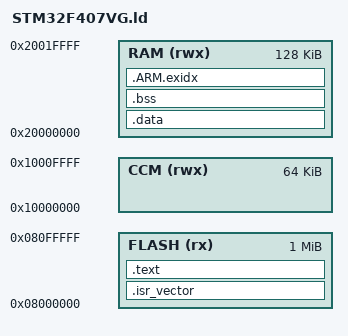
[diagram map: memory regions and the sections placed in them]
/* Linker script for STM32F407VGT6
 * Register values from general knowledge — NOT MCP-verified.
 * Flash: 1024KB, RAM: 128KB (plus 64KB CCM)
 */

MEMORY
{
    FLASH (rx)  : ORIGIN = 0x08000000, LENGTH = 1024K
    RAM   (rwx) : ORIGIN = 0x20000000, LENGTH = 128K
    CCM   (rwx) : ORIGIN = 0x10000000, LENGTH = 64K
}

_estack = ORIGIN(RAM) + LENGTH(RAM);

SECTIONS
{
    .isr_vector :
    {
        KEEP(*(.isr_vector))
    } > FLASH

    .text :
    {
        . = ALIGN(4);
        *(.text)
        *(.text*)
        *(.rodata)
        *(.rodata*)
        . = ALIGN(4);
        _etext = .;
    } > FLASH

    _sidata = LOADADDR(.data);

    .data : AT (_etext)
    {
        . = ALIGN(4);
        _sdata = .;
        *(.data)
        *(.data*)
        . = ALIGN(4);
        _edata = .;
    } > RAM

    .bss :
    {
        . = ALIGN(4);
        _sbss = .;
        *(.bss)
        *(.bss*)
        *(COMMON)
        . = ALIGN(4);
        _ebss = .;
    } > RAM

    /* Define end for sbrk (heap starts here) */
    end = .;

    /* Exception index table (unwind info) */
    .ARM.exidx : AT (LOADADDR(.data) + SIZEOF(.data))
    {
        . = ALIGN(4);
        __exidx_start = .;
        *(.ARM.exidx*)
        __exidx_end = .;
    } > RAM
}
